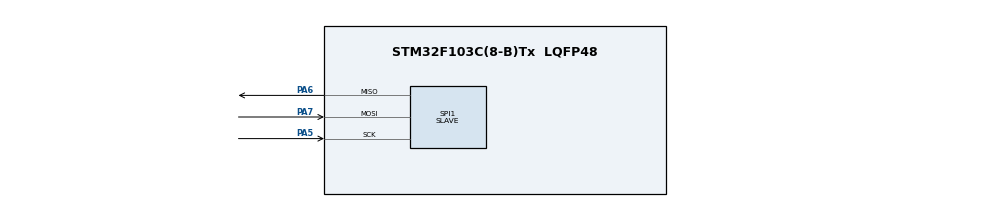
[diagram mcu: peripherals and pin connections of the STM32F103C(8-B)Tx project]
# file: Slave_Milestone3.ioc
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Mcu.Family=STM32F1
Mcu.Name=STM32F103C(8-B)Tx
Mcu.Package=LQFP48
NVIC.PriorityGroup=NVIC_PRIORITYGROUP_4
PA5.Mode=Full_Duplex_Slave
PA5.Signal=SPI1_SCK
PA6.Mode=Full_Duplex_Slave
PA6.Signal=SPI1_MISO
PA7.Mode=Full_Duplex_Slave
PA7.Signal=SPI1_MOSI
ProjectManager.HeapSize=0x200
ProjectManager.StackSize=0x400
ProjectManager.TargetToolchain=STM32CubeIDE
RCC.APB1Freq_Value=8000000
RCC.APB2Freq_Value=8000000
SPI1.Direction=SPI_DIRECTION_2LINES
SPI1.Mode=SPI_MODE_SLAVE
SPI1.VirtualType=VM_SLAVE
VP_SYS_VS_ND.Mode=No_Debug
board=custom

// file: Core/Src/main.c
/* USER CODE BEGIN Header */
/**
  ******************************************************************************
  * @file           : main.c
  * @brief          : Main program body
  ******************************************************************************
  * @attention
  *
  * Copyright (c) 2026 STMicroelectronics.
  * All rights reserved.
  *
  * This software is licensed under terms that can be found in the LICENSE file
  * in the root directory of this software component.
  * If no LICENSE file comes with this software, it is provided AS-IS.
  *
  ******************************************************************************
  */
/* USER CODE END Header */
#include "main.h"

/* USER CODE BEGIN PTD */
typedef struct {
    uint16_t id;
    float voltage;
    uint16_t speed;
} CaseData;

CaseData cases[5] = {
    {0x1001, 12.3, 200},
    {0x1002, 14.2, 150},
    {0x1003, 13.8, 100},
    {0x1004, 11.5, 220},
    {0x1005, 10.9, 280}
};
/* USER CODE END PTD */

SPI_HandleTypeDef hspi1;

void SystemClock_Config(void);
static void MX_GPIO_Init(void);
static void MX_SPI1_Init(void);

int main(void)
{

  /* MCU Configuration--------------------------------------------------------*/

  /* Reset of all peripherals, Initializes the Flash interface and the Systick. */
  HAL_Init();

  /* Configure the system clock */
  SystemClock_Config();

  /* Initialize all configured peripherals */
  MX_GPIO_Init();
  MX_SPI1_Init();
  /* USER CODE BEGIN 2 */
  // The instructions require setting NSS_HARD_INPUT manually here

  uint8_t rx_buffer[3] = {0};
  uint8_t tx_buffer[3] = {0};

  hspi1.Init.NSS = SPI_NSS_HARD_INPUT;
  HAL_SPI_Init(&hspi1);
  /* USER CODE END 2 */

  /* Infinite loop */
  while (1)
  {

    /* USER CODE BEGIN 3 */
	  // Wait for the Master to clock the line.
	      // This receives the ID, and sends whatever was prepared last time!
	      HAL_SPI_TransmitReceive(&hspi1, tx_buffer, rx_buffer, 3, HAL_MAX_DELAY);

	      int requested_id = rx_buffer[0]; // Read what the master just sent

	      // Prepare the tx_buffer so it is ready for the NEXT time the master asks
	      if(requested_id >= 1 && requested_id <= 5) {
	          uint16_t raw_volt = (uint16_t)(cases[requested_id - 1].voltage * 10);
	          uint16_t raw_speed = cases[requested_id - 1].speed;

	          // Encode these two 12-bit numbers into 24 bits
	          tx_buffer[0] = (raw_volt >> 4) & 0xFF;
	          tx_buffer[1] = ((raw_volt & 0x0F) << 4) | ((raw_speed >> 8) & 0x0F);
	          tx_buffer[2] = raw_speed & 0xFF;
	      }
  }
  /* USER CODE END 3 */
}

void SystemClock_Config(void)
{
  RCC_OscInitTypeDef RCC_OscInitStruct = {0};
  RCC_ClkInitTypeDef RCC_ClkInitStruct = {0};

  /** Initializes the RCC Oscillators according to the specified parameters
  * in the RCC_OscInitTypeDef structure.
  */
  RCC_OscInitStruct.OscillatorType = RCC_OSCILLATORTYPE_HSI;
  RCC_OscInitStruct.HSIState = RCC_HSI_ON;
  RCC_OscInitStruct.HSICalibrationValue = RCC_HSICALIBRATION_DEFAULT;
  RCC_OscInitStruct.PLL.PLLState = RCC_PLL_NONE;
  if (HAL_RCC_OscConfig(&RCC_OscInitStruct) != HAL_OK)
  {
    Error_Handler();
  }

  /** Initializes the CPU, AHB and APB buses clocks
  */
  RCC_ClkInitStruct.ClockType = RCC_CLOCKTYPE_HCLK|RCC_CLOCKTYPE_SYSCLK
                              |RCC_CLOCKTYPE_PCLK1|RCC_CLOCKTYPE_PCLK2;
  RCC_ClkInitStruct.SYSCLKSource = RCC_SYSCLKSOURCE_HSI;
  RCC_ClkInitStruct.AHBCLKDivider = RCC_SYSCLK_DIV1;
  RCC_ClkInitStruct.APB1CLKDivider = RCC_HCLK_DIV1;
  RCC_ClkInitStruct.APB2CLKDivider = RCC_HCLK_DIV1;

  if (HAL_RCC_ClockConfig(&RCC_ClkInitStruct, FLASH_LATENCY_0) != HAL_OK)
  {
    Error_Handler();
  }
}

static void MX_SPI1_Init(void)
{

  /* SPI1 parameter configuration*/
  hspi1.Instance = SPI1;
  hspi1.Init.Mode = SPI_MODE_SLAVE;
  hspi1.Init.Direction = SPI_DIRECTION_2LINES;
  hspi1.Init.DataSize = SPI_DATASIZE_8BIT;
  hspi1.Init.CLKPolarity = SPI_POLARITY_LOW;
  hspi1.Init.CLKPhase = SPI_PHASE_1EDGE;
  hspi1.Init.NSS = SPI_NSS_SOFT;
  hspi1.Init.FirstBit = SPI_FIRSTBIT_MSB;
  hspi1.Init.TIMode = SPI_TIMODE_DISABLE;
  hspi1.Init.CRCCalculation = SPI_CRCCALCULATION_DISABLE;
  hspi1.Init.CRCPolynomial = 10;
  if (HAL_SPI_Init(&hspi1) != HAL_OK)
  {
    Error_Handler();
  }

}

static void MX_GPIO_Init(void)
{

  /* GPIO Ports Clock Enable */
  __HAL_RCC_GPIOA_CLK_ENABLE();

}

void Error_Handler(void)
{
  __disable_irq();
  while (1)
  {
  }
}
